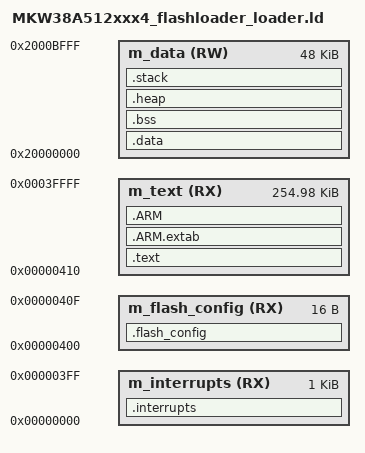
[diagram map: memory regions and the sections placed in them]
/*
** ###################################################################
**     Processor:           MKW38A512VFT4
**     Compiler:            GNU C Compiler
**     Reference manual:    MKW38A512RM Rev. 5, 05/2018
**     Version:             rev. 1.0, 2018-06-25
**     Build:               b190226
**
**     Abstract:
**         Linker file for the GNU C Compiler
**
**     Copyright 2016 Freescale Semiconductor, Inc.
**     Copyright 2016-2020 NXP
**     All rights reserved.
**
**     SPDX-License-Identifier: BSD-3-Clause
**
**     http:                 www.nxp.com
**     mail:                 support@nxp.com
**
** ###################################################################
*/

/* Entry Point */
ENTRY(Reset_Handler)

HEAP_SIZE  = DEFINED(__heap_size__)  ? __heap_size__  : 0x0;
STACK_SIZE = DEFINED(__stack_size__) ? __stack_size__ : 0x0400;

/* Specify the memory areas */
MEMORY
{
  m_interrupts          (RX)  : ORIGIN = 0x00000000, LENGTH = 0x00000400
  m_flash_config        (RX)  : ORIGIN = 0x00000400, LENGTH = 0x00000010
  m_text                (RX)  : ORIGIN = 0x00000410, LENGTH = 0x0003FBF0
  m_data                (RW)  : ORIGIN = 0x20000000, LENGTH = 0x0000C000
}

GROUP (
  libnosys.a
  libgcc.a
  libc_nano.a
  libm.a
  libcr_newlib_none.a
)

/* Define output sections */
SECTIONS
{
  /* The startup code goes first into internal flash */
  .interrupts :
  {
    __VECTOR_TABLE = .;
    . = ALIGN(4);
    KEEP(*(.isr_vector))     /* Startup code */
    . = ALIGN(4);
  } > m_interrupts

  .flash_config :
  {
    . = ALIGN(4);
    KEEP(*(.FlashConfig))    /* Flash Configuration Field (FCF) */
    . = ALIGN(4);
  } > m_flash_config

  /* The program code and other data goes into internal flash */
  .text :
  {
    . = ALIGN(4);
    *(.text)                 /* .text sections (code) */
    *(.text*)                /* .text* sections (code) */
    *(.rodata)               /* .rodata sections (constants, strings, etc.) */
    *(.rodata*)              /* .rodata* sections (constants, strings, etc.) */
    . = ALIGN(4);
  } > m_text

  .ARM.extab :
  {
    *(.ARM.extab* .gnu.linkonce.armextab.*)
  } > m_text

  .ARM :
  {
    __exidx_start = .;
    *(.ARM.exidx*)
    __exidx_end = .;
  } > m_text

  __etext = .;    /* define a global symbol at end of code */
  __DATA_ROM = .; /* Symbol is used by startup for data initialization */

  .data : AT(__DATA_ROM)
  {
    . = ALIGN(4);
    __DATA_RAM = .;
    __data_start__ = .;      /* create a global symbol at data start */
    *(.data)                 /* .data sections */
    *(.data*)                /* .data* sections */
    . = ALIGN(4);
    __data_end__ = .;        /* define a global symbol at data end */
  } > m_data

  __DATA_END = __DATA_ROM + (__data_end__ - __data_start__);

  /* Uninitialized data section */
  .bss :
  {
    /* This is used by the startup in order to initialize the .bss section */
    . = ALIGN(4);
    __START_BSS = .;
    __bss_start__ = .;
    *(.bss)
    *(.bss*)
    *(COMMON)
    . = ALIGN(4);
    __bss_end__ = .;
    __END_BSS = .;
  } > m_data

  .heap :
  {
    . = ALIGN(8);
    __end__ = .;
    PROVIDE(end = .);
    PROVIDE(_pvHeapStart = .);
    __HeapBase = .;
    . += HEAP_SIZE;
    __HeapLimit = .;
    __heap_limit = .; /* Add for _sbrk */
  } > m_data

  .stack :
  {
    . = ALIGN(8);
    . += STACK_SIZE;
  } > m_data

  /* Initializes stack on the end of block */
  __StackTop   = ORIGIN(m_data) + LENGTH(m_data);
  __StackLimit = __StackTop - STACK_SIZE;
  PROVIDE(__stack = __StackTop);

  .ARM.attributes 0 : { *(.ARM.attributes) }

  ASSERT(__StackLimit >= __HeapLimit, "region m_data overflowed with stack and heap")
}

